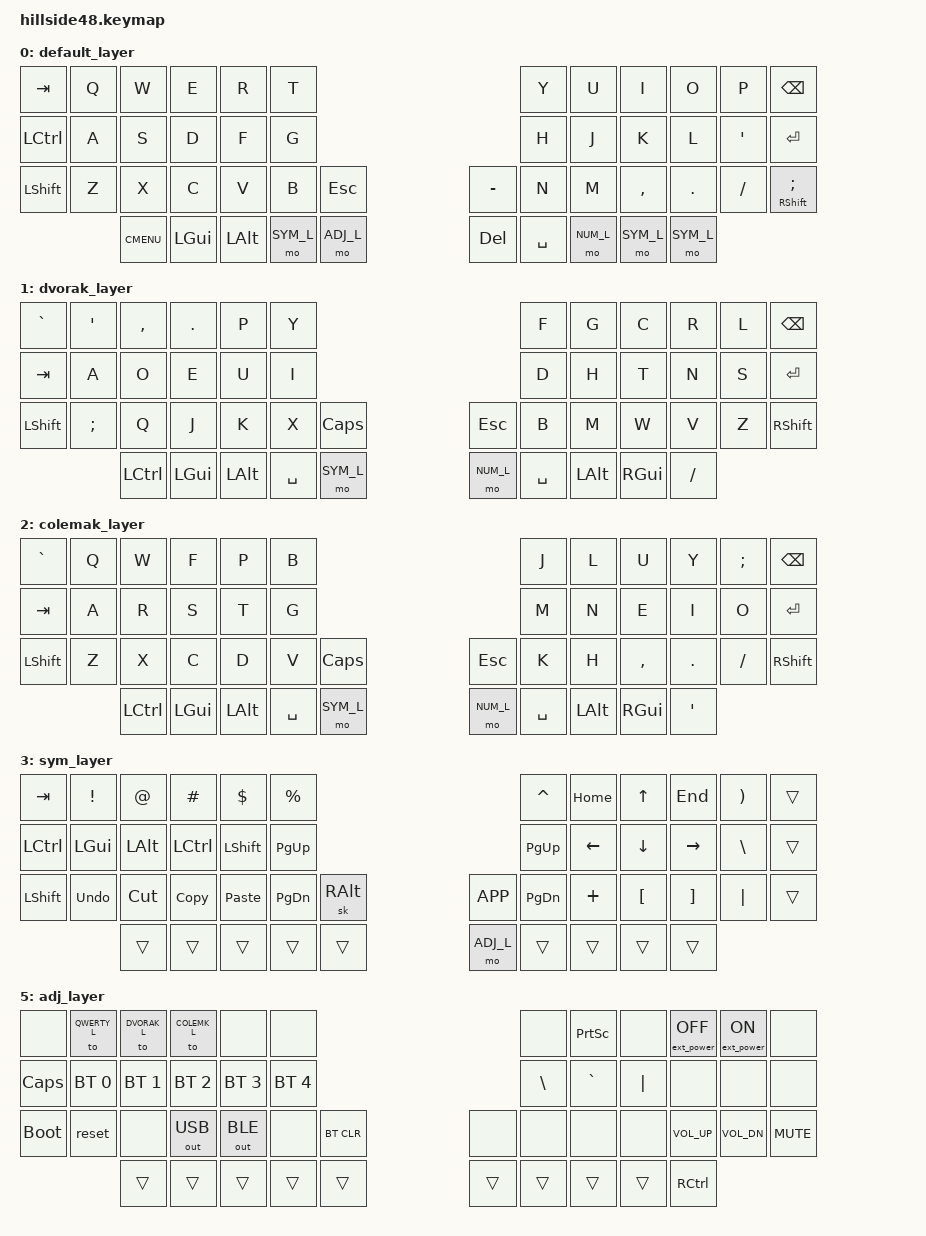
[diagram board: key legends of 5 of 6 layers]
/*
 * Copyright (c) 2022 The ZMK Contributors
 *
 * SPDX-License-Identifier: MIT
 */

#include <behaviors.dtsi>
#include <dt-bindings/zmk/bt.h>
#include <dt-bindings/zmk/ext_power.h>
#include <dt-bindings/zmk/keys.h>
#include <dt-bindings/zmk/outputs.h>

#define QWERTY_L 0
#define DVORAK_L 1
#define COLEMK_L 2
#define SYM_L    3
#define NUM_L    4
#define ADJ_L    5

#define Undo   LC(Z)
#define Cut    LC(X)
#define Copy   LC(C)
#define Paste  LC(V)

/ {
        keymap {
                compatible = "zmk,keymap";

                default_layer {
/* QWERTY
 * -------------------------------------------------------------------------------------------------------------------------------------
 * | TAB   |   Q   |   W   |   E   |   R   |   T   |-----------------------------------|   Y   |   U   |   I   |   O   |   P   | BKSPC |
 * | CTRL  |   A   |   S   |   D   |   F   |   G   |-----------------------------------|   H   |   J   |   K   |   L   |   ;   | ENTER |
 * | SHIFT |   Z   |   X   |   C   |   V   |   B   | ESC  |-------------------|  DASH |   N   |   M   |   ,   |   .   |   /   | SHIFT/' |
 * ----------------| MENU  |-------|  GUI  |  ALT  | Nav  |  Adj  |---|  DEL  | SPACE |  Num  |  GUI  |-------|   '   |----------------
 */
                        bindings = <
&kp  TAB      &kp  Q        &kp  W        &kp  E        &kp  R        &kp  T                                                                         &kp  Y        &kp  U        &kp  I        &kp  O        &kp  P        &kp  BSPC
&kp  LCTRL    &kp  A        &kp  S        &kp  D        &kp  F        &kp  G                                                                         &kp  H        &kp  J        &kp  K        &kp  L        &kp  SQT      &kp  ENTER  
&kp  LSHFT    &kp  Z        &kp  X        &kp  C        &kp  V        &kp  B        &kp  ESC                                           &kp  MINUS    &kp  N        &kp  M        &kp  COMMA    &kp  DOT      &kp  SLASH    &mt  RSHFT SEMI
                            &kp  K_CMENU                &kp  LGUI     &kp  LALT     &mo  SYM_L    &mo  ADJ_L             &kp DEL       &kp  SPACE    &mo  NUM_L    &mo  SYM_L                  &mo  SYM_L   
                        >;
			
                        sensor-bindings = <&inc_dec_kp C_VOL_UP C_VOL_DN &inc_dec_kp PG_UP PG_DN>;
                };
		
                dvorak_layer {
/* DVORAK
 * -------------------------------------------------------------------------------------------------------------------------------------
 * | `     |   '   |   ,   |   .   |   P   |   Y   |-----------------------------------|   F   |   G   |   C   |   R   |   L   | BKSPC |
 * | TAB   |   A   |   O   |   E   |   U   |   I   |-----------------------------------|   D   |   H   |   T   |   N   |   S   | ENTER |
 * | SHIFT |   ;   |   Q   |   J   |   K   |   X   | CAPS  |-------------------|  ESC  |   B   |   M   |   W   |   V   |   Z   | SHIFT |
 * ----------------| CTRL  |-------|  GUI  |  ALT  | SPACE |  Sym  |---|  Num  | SPACE |  ALT  |  GUI  |-------|   /   |----------------
 */
                        bindings = <
&kp  GRAVE    &kp  SQT      &kp  COMMA    &kp  DOT      &kp  P        &kp  Y                                                                         &kp  F        &kp  G        &kp  C        &kp  R        &kp  L        &kp  BSPC
&kp  TAB      &kp  A        &kp  O        &kp  E        &kp  U        &kp  I                                                                         &kp  D        &kp  H        &kp  T        &kp  N        &kp  S        &kp  ENTER
&kp  LSHFT    &kp  SEMI     &kp  Q        &kp  J        &kp  K        &kp  X        &kp  CAPS                                          &kp   ESC     &kp  B        &kp  M        &kp  W        &kp  V        &kp  Z        &kp  RSHFT
                            &kp  LCTRL                  &kp  LGUI     &kp  LALT     &kp  SPACE    &mo  SYM_L             &mo  NUM_L    &kp  SPACE    &kp  LALT     &kp  RGUI                   &kp  SLASH
                        >;
			
                        sensor-bindings = <&inc_dec_kp C_VOL_UP C_VOL_DN &inc_dec_kp PG_UP PG_DN>;
                };
		
                colemak_layer {
/* COLEMAK-DH
 * -------------------------------------------------------------------------------------------------------------------------------------
 * | `     |   Q   |   W   |   F   |   P   |   B   |-----------------------------------|   J   |   L   |   U   |   Y   |   ;   | BKSPC |
 * | TAB   |   A   |   R   |   S   |   T   |   G   |-----------------------------------|   M   |   N   |   E   |   I   |   O   | ENTER |
 * | SHIFT |   Z   |   X   |   C   |   D   |   V   | CAPS  |-------------------|  ESC  |   K   |   H   |   ,   |   .   |   /   | SHIFT |
 * ----------------| CTRL  |-------|  GUI  |  ALT  | SPACE |  Sym  |---|  Num  | SPACE |  ALT  |  GUI  |-------|   '   |----------------
 */
                        bindings = <
&kp  GRAVE    &kp  Q        &kp  W        &kp  F        &kp  P        &kp  B                                                                         &kp  J        &kp  L        &kp  U        &kp  Y        &kp  SEMI     &kp  BSPC
&kp  TAB      &kp  A        &kp  R        &kp  S        &kp  T        &kp  G                                                                         &kp  M        &kp  N        &kp  E        &kp  I        &kp  O        &kp  ENTER
&kp  LSHFT    &kp  Z        &kp  X        &kp  C        &kp  D        &kp  V        &kp  CAPS                                          &kp   ESC     &kp  K        &kp  H        &kp  COMMA    &kp  DOT      &kp  SLASH    &kp  RSHFT
                            &kp  LCTRL                  &kp  LGUI     &kp  LALT     &kp  SPACE    &mo  SYM_L             &mo  NUM_L    &kp  SPACE    &kp  LALT     &kp  RGUI                   &kp  SQT   
                        >;
			
                        sensor-bindings = <&inc_dec_kp C_VOL_UP C_VOL_DN &inc_dec_kp PG_UP PG_DN>;
                };
		
                sym_layer {
/* SYM
 * -------------------------------------------------------------------------------------------------------------------------------------
 * | TAB   |   !   |   @   |   #   |   $   |   %   |-----------------------------------|   ^   |   HOME   |   UP   |   END   |   )   | BSPC  |
 * | CTRL  |  GUI  |  Alt  | Ctrl  | Shift | Pg Up |-----------------------------------|   PG UP   |   LEFT   |   DOWN   |   RIGHT   |   \   | ENTER |
 * | SHIFT |  UnDo |  Cut  | Copy  | Paste | Pg Dn |OsAltGr|-------------------| MENU  |   PG DN   |   +   |   {   |   }   |   |   | SHIFT |
 * ----------------|       |-------|       |       |       |       |---| ADJ_L |       |       |       |-------|    |----------------
 */
                        bindings = <
&kp  TAB     &kp  EXCL     &kp  AT       &kp  HASH     &kp  DOLLAR   &kp  PERCENT                                                                   &kp  CARET    &kp  HOME     &kp  UP       &kp  END      &kp  RPAR     &trans
&kp  LCTRL   &kp  LGUI     &kp  LALT     &kp  LCTRL    &kp  LSHFT    &kp  PG_UP                                                                     &kp  PG_UP    &kp  LEFT     &kp  DOWN     &kp  RIGHT    &kp  BSLH     &trans
&kp  LSHFT   &kp  Undo     &kp  Cut      &kp  Copy     &kp  Paste    &kp  PG_DN    &sk  RALT                                          &kp  K_APP    &kp  PG_DN    &kp  PLUS     &kp  LBKT     &kp  RBKT     &kp  PIPE     &trans
                            &trans                     &trans        &trans        &trans        &trans                 &mo  ADJ_L    &trans        &trans        &trans                      &trans    
                        >;
			
                        sensor-bindings = <&inc_dec_kp PG_UP PG_DN &inc_dec_kp C_VOL_UP C_VOL_DN>;
                };
		
                num_layer {
/* NUM   
 * -------------------------------------------------------------------------------------------------------------------------------------
 * | F11   |   1   |   2   |   3   |   4   |   5   |-----------------------------------|   6   |   7   |   8   |   9   |       | BSPC  |
 * | F12   |  !   |  @   |  #   |  $   |  %   |-----------------------------------| ^  |   &   |  *    |   (   |   )   |       |
 * | Shift |  F1   |  F2   |  F3   |  F4   |  F5  |  INS  |------------------- |  F6   |  F7   |  F8   |  F9   | F10   | Right | DELETE|
 * ----------------|       |-------|       |       |       | ADJ_L |---|       |       |       |       |-------| CTRL  |----------------
 */
                        bindings = <
&kp  TAB      &kp  N1       &kp  N2       &kp  N3       &kp  N4       &kp  N5                                                                        &kp   N6      &kp   N7      &kp   N8      &kp   N9      &kp  N0       &trans
&kp  LCTRL    &kp  EXCL     &kp  AT       &kp  HASH     &kp  DOLLAR   &kp  PERCENT                                                                   &kp  CARET    &kp  AMPS     &kp  ASTRK    &kp  LPAR     &kp  RPAR     &trans
&kp  LSHFT    &kp  F1       &kp  F2       &kp  F3       &kp  F4       &kp  F5     &kp INS                                              &kp  F6       &kp  F7       &kp  F8       &kp  F9       &kp  F10      &kp DEL
                            &kp KP_MULTIPLY             &kp KP_DIVIDE   &kp KP_PLUS    &kp KP_MINUS    &mo ADJ_L                       &kp LALT      &trans        &trans        &kp  LBRC                   &kp  RBRC   
                        >;
			
                        sensor-bindings = <&inc_dec_kp PG_UP PG_DN &inc_dec_kp C_VOL_UP C_VOL_DN>;
                };
		
                adj_layer {
/* ADJUST
 * -------------------------------------------------------------------------------------------------------------------------------------
 * |       | QWERTY| DVORAK| COLEMK|       |       |-----------------------------------|       |Prt Scr|       | EP_OFF| EP_ON |       |
 * | CAPS  | BT 0  | BT 1  | BT 2  | BT 3  | BT 4  |-----------------------------------|       |       |       |       |       |       |
 * | BOOTL | RESET |       |OUT_USB|OUT_BLE|       |BT CLR |-------------------|       |       |       |       |  Vol Up     |  Vol Dn    | Mute |
 * ----------------|       |-------|       |       |       |       |---|       |       |       |       |-------| CTRL  |----------------
 */
                        bindings = <
&none         &to  QWERTY_L &to  DVORAK_L &to  COLEMK_L &none         &none                                                                             &none             &kp PRINTSCREEN    &none         &ext_power EP_OFF  &ext_power EP_ON &none
&kp  CAPS     &bt  BT_SEL 0 &bt  BT_SEL 1 &bt  BT_SEL 2 &bt  BT_SEL 3 &bt  BT_SEL 4                                                                     &kp  BSLH         &kp  GRAVE         &kp  PIPE     &none              &none            &none
&bootloader   &reset        &none         &out OUT_USB  &out OUT_BLE  &none         &bt BT_CLR                                         &none            &none             &none              &none         &kp  C_VOL_UP      &kp  C_VOL_DN    &kp  C_MUTE
                            &trans                      &trans        &trans        &trans        &trans                 &trans        &trans           &trans            &trans                           &kp  RCTRL   
                        >;
			
                        sensor-bindings = <&inc_dec_kp C_VOL_UP C_VOL_DN &inc_dec_kp PG_UP PG_DN>;
                };
        };
};
